# AltaRiscv register map
File version: 1.0
Registers are 32-bit, read-write, reset 0x0 unless marked. A register's access mark holds for its fields unless they carry their own. Offsets are from the block's base; [hi:lo] are bit positions; lines under a group give offsets from that group; {n}, {i} and the like mark numbered series.

## DMAC0 — DMAC registers
Base 0x41000000
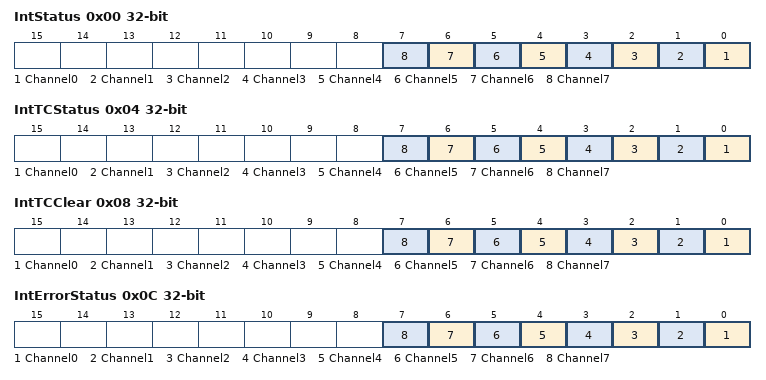
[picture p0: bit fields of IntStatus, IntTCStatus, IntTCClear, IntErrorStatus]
0x00 IntStatus ro — Interrupt Status Register
  [n] Channel{n} (n=0..7)
0x04 IntTCStatus ro — Interrupt Terminal Count Status Register
  [n] Channel{n} (n=0..7)
0x08 IntTCClear wo — Interrupt Terminal Count Clear Register
  [n] Channel{n} (n=0..7)
0x0C IntErrorStatus ro — Interrupt Error Status Register
  [n] Channel{n} (n=0..7)
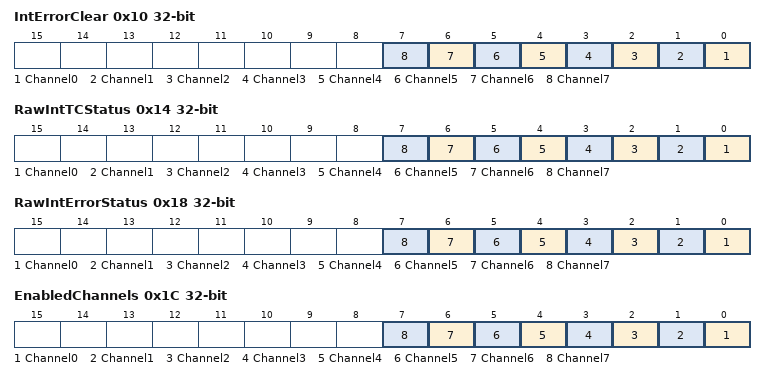
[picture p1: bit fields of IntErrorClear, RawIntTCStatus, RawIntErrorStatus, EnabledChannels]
0x10 IntErrorClear wo — Interrupt Error Clear Register
  [n] Channel{n} (n=0..7)
0x14 RawIntTCStatus ro — Raw Interrupt Terminal Count Status Register
  [n] Channel{n} (n=0..7)
0x18 RawIntErrorStatus ro — Raw Error Interrupt Status Register
  [n] Channel{n} (n=0..7)
0x1C EnabledChannels ro — Enabled Channel Register
  [n] Channel{n} (n=0..7)
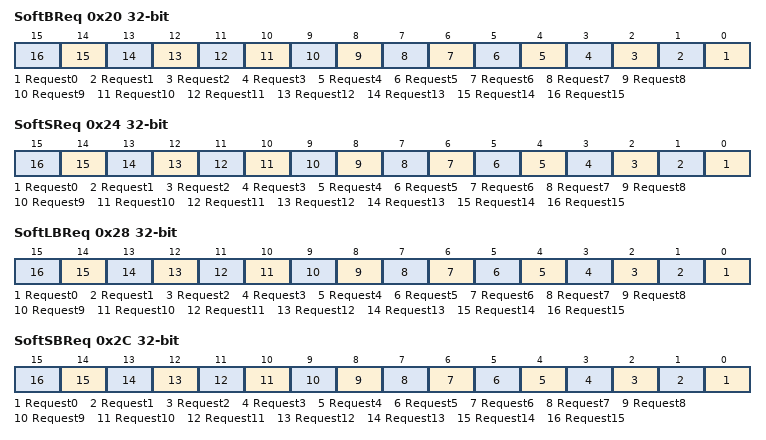
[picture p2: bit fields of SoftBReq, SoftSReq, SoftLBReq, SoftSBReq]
0x20 SoftBReq — Software Burst Request Register
  [n] Request{n} (n=0..15)
0x24 SoftSReq — Software Single Request Register
  [n] Request{n} (n=0..15)
0x28 SoftLBReq — Software Last Burst Request Register
  [n] Request{n} (n=0..15)
0x2C SoftSBReq — Software Last Single Request Register
  [n] Request{n} (n=0..15)
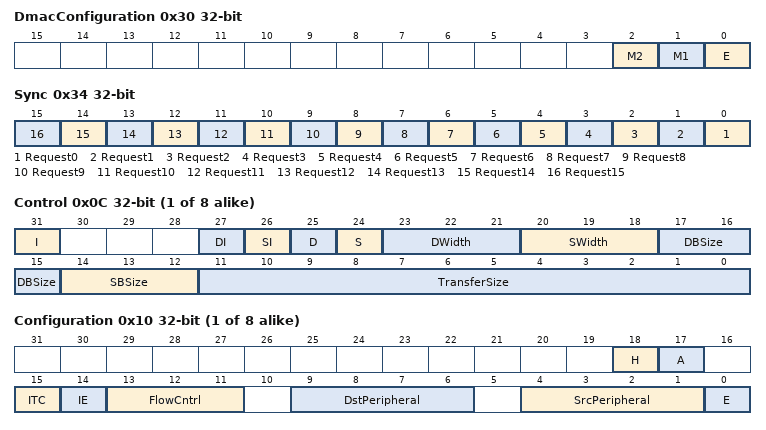
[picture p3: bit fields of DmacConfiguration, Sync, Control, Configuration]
0x30 DmacConfiguration — Configuration Register
  [2] M2 — AHB Master 2 endianness
    0=LE; 1=BE
  [1] M1 — AHB Master 1 endianness
    0=LE; 1=BE
  [0] E — DMAC enable
0x34 Sync — Synchronization Register
  [n] Request{n} (n=0..15)
{0x100+0x20*i} Channel{i} (i=0..7) group — Channel Registers
  0x00 SrcAddr — Channel Source Address Register
  0x04 DstAddr — Channel Destination Address Register
  0x08 LLI — Channel Linked List Item Register
  0x0C Control — Channel Control Register
    [31] I — Terminal count interrupt enable
    [27] DI — Destination increment
    [26] SI — Source increment
    [25] D — Destination AHB master select
    [24] S — Source AHB master select
    [23:21] DWidth — Destination transfer width
      0=8-bit; 1=16-bit; 2=32-bit
    [20:18] SWidth — Source transfer width
      0=8-bit; 1=16-bit; 2=32-bit
    [17:15] DBSize — Destination burst size
      0=1; 1=4; 2=8; 3=16; 4=32; 5=64; 6=128; 7=256
    [14:12] SBSize — Source burst size
      0=1; 1=4; 2=8; 3=16; 4=32; 5=64; 6=128; 7=256
    [11:0] TransferSize
  0x10 Configuration access per field — Channel Configuration Register
    [18] H rw — Halt
    [17] A ro — Active
    [15] ITC rw — Terminal count interrupt mask
    [14] IE rw — Interrupt error mask
    [13:11] FlowCntrl rw — Flow control
      0=MEM_TO_MEM_DMA_CTRL; 1=MEM_TO_PER_DMA_CTRL; 2=PER_TO_MEM_DMA_CTRL; 3=PER_TO_PER_DMA_CTRL; 4=PER_TO_PER_DST_CTRL; 5=MEM_TO_PER_PER_CTRL; 6=PER_TO_MEM_PER_CTRL; 7=PER_TO_PER_SRC_CTRL
    [9:6] DstPeripheral rw — Destination peripheral
    [4:1] SrcPeripheral rw — Source peripheral
    [0] E rw — Channel enable

## CRC0 — CRC registers
Base 0x41002000
0x00 DR — CRC Data register
0x04 IDR — CRC Independent data register
  [7:0] IDR
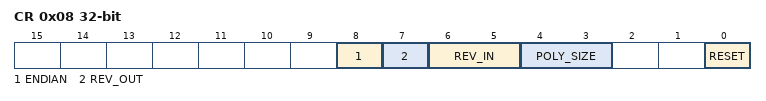
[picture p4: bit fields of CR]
0x08 CR access per field — CRC Control register
  [8] ENDIAN rw — Input Endianness
    0=BE; 1=LE
  [7] REV_OUT rw — Reverse output data
    0=None; 1=Reversed
  [6:5] REV_IN rw — Reverse input data
    0=None; 1=By byte; 2=By half-word; 3=By word
  [4:3] POLY_SIZE rw — Polynomial size
    0=32 bit; 1=16 bit; 2=8 bit; 3=7 bit
  [0] RESET wo — Reset bit
0x10 INIT — Initial CRC value register
0x14 POL — CRC polynomial register

## MAC0 — MAC registers
Base 0x41040000
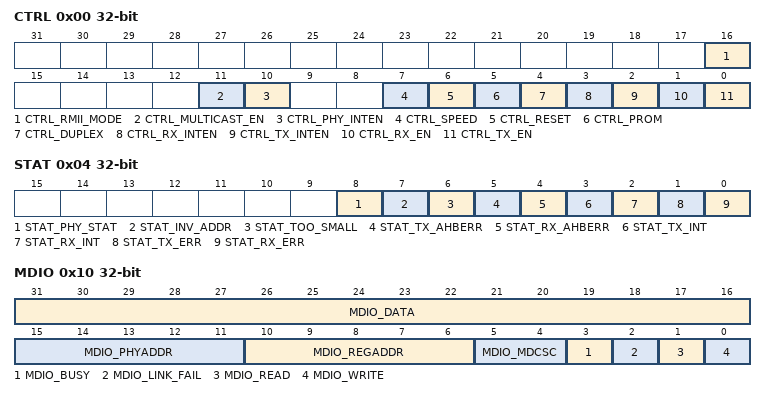
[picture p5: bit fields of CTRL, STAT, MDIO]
0x00 CTRL — Control register
  [16] CTRL_RMII_MODE — RMII mode
    0=MII; 1=RMII
  [11] CTRL_MULTICAST_EN — Multicast enable
  [10] CTRL_PHY_INTEN — PHY status change interrupt enable
  [7] CTRL_SPEED — Speed
    0=10M; 1=100M
  [6] CTRL_RESET — Reset, self clearing
  [5] CTRL_PROM — Promiscuous mode
  [4] CTRL_DUPLEX — Duplex mode
    0=Half duplex; 1=Full duplex
  [3] CTRL_RX_INTEN — Receive interrupt enable
  [2] CTRL_TX_INTEN — Transmit interrupt enable
  [1] CTRL_RX_EN — Receive enable
  [0] CTRL_TX_EN — Transmit enable
0x04 STAT — Status register
  [8] STAT_PHY_STAT — PHY status change
  [7] STAT_INV_ADDR — Invalid address
  [6] STAT_TOO_SMALL — Too small. Packet received is smaller than minimum size
  [5] STAT_TX_AHBERR — Transmit AHB error
  [4] STAT_RX_AHBERR — Receive AHB error
  [3] STAT_TX_INT — Transmit interrupt
  [2] STAT_RX_INT — Receive interrupt
  [1] STAT_TX_ERR — Transmit error
  [0] STAT_RX_ERR — Receive error
0x08 MACMSB — Mac address MSB
0x0C MACLSB — Mac address LSB
0x10 MDIO access per field — MDIO control and status register
  [31:16] MDIO_DATA rw — Data to/from PHY
  [15:11] MDIO_PHYADDR rw — PHY address
  [10:6] MDIO_REGADDR rw — Register address
  [5:4] MDIO_MDCSC rw — MDC Scaler
    0=Div 128; 1=Div 64; 2=Div 32; 3=Div 16
  [3] MDIO_BUSY ro — MDIO busy, read only
  [2] MDIO_LINK_FAIL ro — Link fail, read only
  [1] MDIO_READ rw
  [0] MDIO_WRITE rw
0x14 TXBASE — Transmit descriptor table base address
0x18 RXBASE — Receive descriptor table base address
0x20 HTMSB — Hash table MSB
0x24 HTLSB — Hash table LSB
